VERSION ""

NS_ :

BS_:

BU_: IECU UPA
VAL_TABLE_ AudibleBeepRate 12 ;
VAL_TABLE_ SensorStatus 1 "Fault" 0 "No Fault" ;
VAL_TABLE_ RadarSensorWorkStatus 3 "Reserved" 2 "Disable" 1 "Active" 0 "Enable" ;

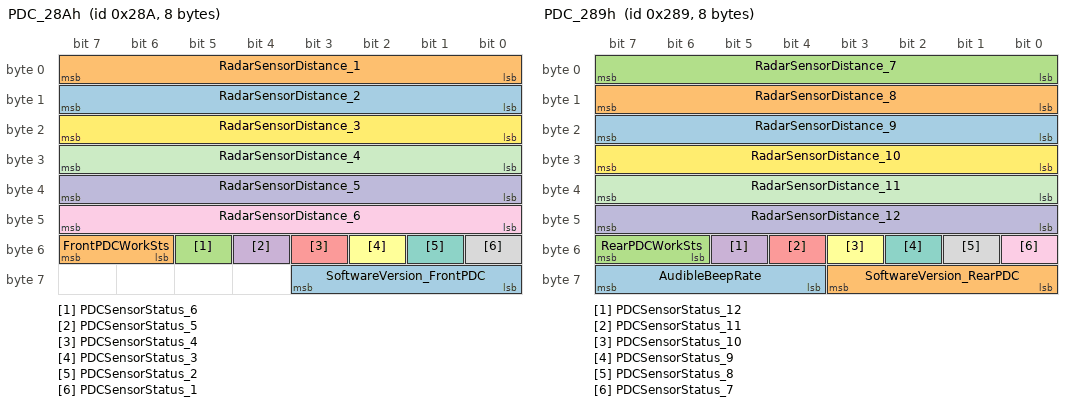
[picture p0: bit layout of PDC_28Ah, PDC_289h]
BO_ 650 PDC_28Ah: 8 UPA
 SG_ SoftwareVersion_FrontPDC : 56|4@1+ (1,0) [0|15] "" Vector__XXX
 SG_ FrontPDCWorkSts : 54|2@1+ (1,0) [0|3] "" Vector__XXX
 SG_ PDCSensorStatus_6 : 53|1@1+ (1,0) [0|1] "" Vector__XXX
 SG_ PDCSensorStatus_5 : 52|1@1+ (1,0) [0|1] "" Vector__XXX
 SG_ PDCSensorStatus_4 : 51|1@1+ (1,0) [0|1] "" Vector__XXX
 SG_ PDCSensorStatus_3 : 50|1@1+ (1,0) [0|1] "" Vector__XXX
 SG_ PDCSensorStatus_2 : 49|1@1+ (1,0) [0|1] "" Vector__XXX
 SG_ PDCSensorStatus_1 : 48|1@1+ (1,0) [0|1] "" Vector__XXX
 SG_ RadarSensorDistance_6 : 40|8@1+ (2,0) [0|510] "cm" Vector__XXX
 SG_ RadarSensorDistance_5 : 32|8@1+ (2,0) [0|510] "cm" Vector__XXX
 SG_ RadarSensorDistance_4 : 24|8@1+ (2,0) [0|510] "cm" Vector__XXX
 SG_ RadarSensorDistance_3 : 16|8@1+ (2,0) [0|510] "cm" Vector__XXX
 SG_ RadarSensorDistance_2 : 8|8@1+ (2,0) [0|510] "cm" Vector__XXX
 SG_ RadarSensorDistance_1 : 0|8@1+ (2,0) [0|510] "cm" Vector__XXX

BO_ 649 PDC_289h: 8 UPA
 SG_ AudibleBeepRate : 60|4@1+ (1,0) [0|15] "" Vector__XXX
 SG_ SoftwareVersion_RearPDC : 56|4@1+ (1,0) [0|15] "" Vector__XXX
 SG_ RearPDCWorkSts : 54|2@1+ (1,0) [0|3] "" Vector__XXX
 SG_ PDCSensorStatus_12 : 53|1@1+ (1,0) [0|1] "" Vector__XXX
 SG_ PDCSensorStatus_11 : 52|1@1+ (1,0) [0|1] "" Vector__XXX
 SG_ PDCSensorStatus_10 : 51|1@1+ (1,0) [0|1] "" Vector__XXX
 SG_ PDCSensorStatus_9 : 50|1@1+ (1,0) [0|1] "" Vector__XXX
 SG_ PDCSensorStatus_8 : 49|1@1+ (1,0) [0|1] "" Vector__XXX
 SG_ PDCSensorStatus_7 : 48|1@1+ (1,0) [0|1] "" Vector__XXX
 SG_ RadarSensorDistance_12 : 40|8@1+ (2,0) [0|510] "cm" Vector__XXX
 SG_ RadarSensorDistance_11 : 32|8@1+ (2,0) [0|510] "cm" Vector__XXX
 SG_ RadarSensorDistance_10 : 24|8@1+ (2,0) [0|510] "cm" Vector__XXX
 SG_ RadarSensorDistance_9 : 16|8@1+ (2,0) [0|510] "cm" Vector__XXX
 SG_ RadarSensorDistance_8 : 8|8@1+ (2,0) [0|510] "cm" Vector__XXX
 SG_ RadarSensorDistance_7 : 0|8@1+ (2,0) [0|510] "cm" Vector__XXX

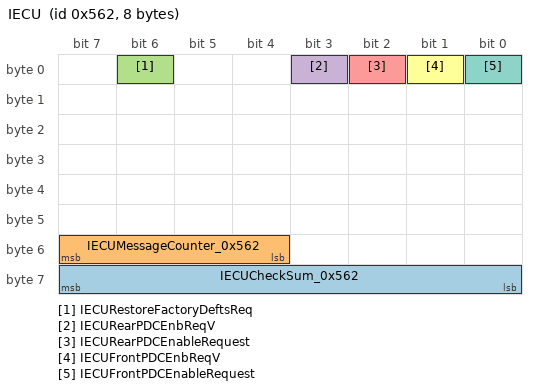
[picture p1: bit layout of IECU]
BO_ 1378 IECU: 8 IECU
 SG_ IECUCheckSum_0x562 : 56|8@1+ (1,0) [0|255] ""  UPA
 SG_ IECUMessageCounter_0x562 : 52|4@1+ (1,0) [0|15] ""  UPA
 SG_ IECURestoreFactoryDeftsReq : 6|1@1+ (1,0) [0|1] ""  UPA
 SG_ IECURearPDCEnbReqV : 3|1@1+ (1,0) [0|1] ""  UPA
 SG_ IECURearPDCEnableRequest : 2|1@1+ (1,0) [0|1] ""  UPA
 SG_ IECUFrontPDCEnbReqV : 1|1@1+ (1,0) [0|1] ""  UPA
 SG_ IECUFrontPDCEnableRequest : 0|1@1+ (1,0) [0|1] ""  UPA
